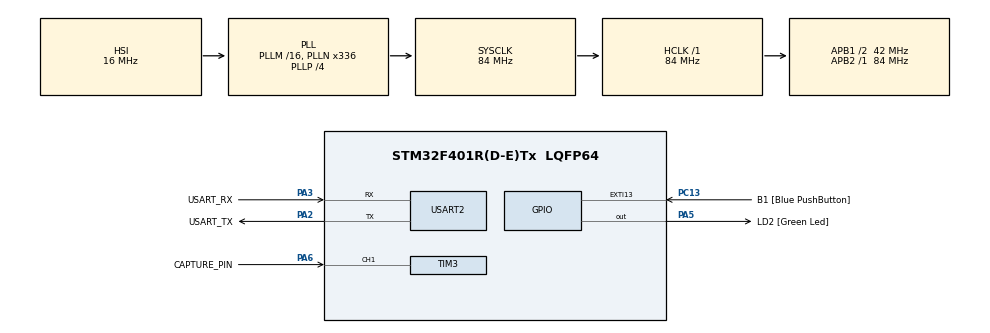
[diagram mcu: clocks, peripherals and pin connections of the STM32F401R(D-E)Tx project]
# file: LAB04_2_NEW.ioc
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Mcu.Family=STM32F4
Mcu.Name=STM32F401R(D-E)Tx
Mcu.Package=LQFP64
NVIC.PriorityGroup=NVIC_PRIORITYGROUP_0
NVIC.TIM2_IRQn=true\:0\:0\:false\:false\:true\:true\:true
NVIC.TIM3_IRQn=true\:0\:0\:false\:false\:true\:true\:true
NVIC.USART2_IRQn=true\:0\:0\:false\:false\:true\:true\:true
PA13.GPIO_Label=TMS
PA13.Mode=Serial_Wire
PA13.Signal=SYS_JTMS-SWDIO
PA14.GPIO_Label=TCK
PA14.Mode=Serial_Wire
PA14.Signal=SYS_JTCK-SWCLK
PA2.GPIO_Label=USART_TX
PA2.GPIO_Mode=GPIO_MODE_AF_PP
PA2.GPIO_PuPd=GPIO_NOPULL
PA2.GPIO_Speed=GPIO_SPEED_FREQ_LOW
PA2.Mode=Asynchronous
PA2.Signal=USART2_TX
PA3.GPIO_Label=USART_RX
PA3.GPIO_Mode=GPIO_MODE_AF_PP
PA3.GPIO_PuPd=GPIO_NOPULL
PA3.GPIO_Speed=GPIO_SPEED_FREQ_LOW
PA3.Mode=Asynchronous
PA3.Signal=USART2_RX
PA5.GPIO_Label=LD2 [Green Led]
PA5.GPIO_Mode=GPIO_MODE_OUTPUT_PP
PA5.GPIO_PuPd=GPIO_NOPULL
PA5.GPIO_Speed=GPIO_SPEED_FREQ_LOW
PA5.Signal=GPIO_Output
PA6.GPIO_Label=CAPTURE_PIN
PA6.Signal=S_TIM3_CH1
PB3.GPIO_Label=SWO
PB3.Signal=SYS_JTDO-SWO
PC13-ANTI_TAMP.GPIO_Label=B1 [Blue PushButton]
PC13-ANTI_TAMP.GPIO_ModeDefaultEXTI=GPIO_MODE_IT_FALLING
PC13-ANTI_TAMP.GPIO_PuPd=GPIO_NOPULL
PC13-ANTI_TAMP.Signal=GPXTI13
PC14-OSC32_IN.Mode=LSE-External-Oscillator
PC14-OSC32_IN.Signal=RCC_OSC32_IN
PC15-OSC32_OUT.Mode=LSE-External-Oscillator
PC15-OSC32_OUT.Signal=RCC_OSC32_OUT
PH0\ -\ OSC_IN.Mode=HSE-External-Clock-Source
PH0\ -\ OSC_IN.Signal=RCC_OSC_IN
PH1\ -\ OSC_OUT.Mode=HSE-External-Clock-Source
PH1\ -\ OSC_OUT.Signal=RCC_OSC_OUT
ProjectManager.HeapSize=0x200
ProjectManager.StackSize=0x400
ProjectManager.TargetToolchain=STM32CubeIDE
RCC.48MHZClocksFreq_Value=48000000
RCC.AHBFreq_Value=84000000
RCC.APB1CLKDivider=RCC_HCLK_DIV2
RCC.APB1Freq_Value=42000000
RCC.APB1TimFreq_Value=84000000
RCC.APB2Freq_Value=84000000
RCC.APB2TimFreq_Value=84000000
RCC.CortexFreq_Value=84000000
RCC.HCLKFreq_Value=84000000
RCC.HSE_VALUE=8000000
RCC.HSI_VALUE=16000000
RCC.PLLN=336
RCC.PLLP=RCC_PLLP_DIV4
RCC.PLLQ=7
RCC.SYSCLKFreq_VALUE=84000000
RCC.SYSCLKSource=RCC_SYSCLKSOURCE_PLLCLK
RCC.VCOOutputFreq_Value=336000000
SH.S_TIM3_CH1.0=TIM3_CH1,Input_Capture1_from_TI1
TIM2.Channel-Output\ Compare1\ No\ Output=TIM_CHANNEL_1
TIM2.Period=999
TIM2.Prescaler=839
TIM3.Channel-Input_Capture1_from_TI1=TIM_CHANNEL_1
USART2.VirtualMode=VM_ASYNC
VP_TIM2_VS_ClockSourceINT.Mode=Internal
VP_TIM2_VS_no_output1.Mode=Output Compare1 No Output
VP_TIM3_VS_ClockSourceINT.Mode=Internal
board=NUCLEO-F401RE

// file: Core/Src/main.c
/* USER CODE BEGIN Header */
/**
  ******************************************************************************
  * @file           : main.c
  * @brief          : Main program body
  ******************************************************************************
  * @attention
  *
  * <h2><center>&copy; Copyright (c) 2023 STMicroelectronics.
  * All rights reserved.</center></h2>
  *
  * This software component is licensed by ST under BSD 3-Clause license,
  * the "License"; You may not use this file except in compliance with the
  * License. You may obtain a copy of the License at:
  *                        opensource.org/licenses/BSD-3-Clause
  *
  ******************************************************************************
  */
/* USER CODE END Header */
#include "main.h"

/* USER CODE BEGIN Includes */
#include "string.h"
#include <stdio.h>
#include <stdlib.h>
/* USER CODE END Includes */

/* USER CODE BEGIN PD */
#define CAPTURING 0
#define DONE 1
#define NONE 0
#define RISING 1
#define FALLING 2
#define MAX_COMPARE_VALUE 91
/* USER CODE END PD */

TIM_HandleTypeDef htim2;
TIM_HandleTypeDef htim3;

UART_HandleTypeDef huart2;

/* USER CODE BEGIN PV */
char msg[30];
char receivedData[3];
char test[] = "\rHo catturato qualcosa!\r\n";
char msg_overflow[] = "\rOverflow!\r\n";
volatile uint8_t number_of_overflows = 0;
volatile uint8_t number_of_overflows_fall = 0;
volatile uint8_t captured_edge = 0;
volatile uint16_t cnt_1 = 0;
volatile uint16_t cnt_2 = 0;
volatile uint16_t cnt_fall = 0;
volatile uint16_t delta_cnt = 0;
volatile uint8_t processing = 0;
volatile uint16_t delta_fall = 0;
volatile uint16_t frequency;
volatile uint8_t max_frequency = 0;
volatile uint8_t min_frequency = 0;
volatile uint8_t dutycycle;
volatile uint8_t read_buffer_new = 0;
volatile uint8_t counting_fall_overflows = 0;
volatile uint8_t counting_overflows = 0;
volatile uint8_t variables_reset = 0;
volatile uint8_t have_received_data = 0;
volatile int8_t opt = 0;
volatile uint8_t step_1 = RESET;
volatile uint8_t step_2 = RESET;
volatile uint8_t step_3 = RESET;
volatile uint8_t compare_value_low = 1;
volatile uint8_t compare_value_high = 11;
uint32_t new_prescaler_value = 4199;
char readBuf[1];
char msg[30];
volatile uint8_t user_choice = 0;
/* USER CODE END PV */

void SystemClock_Config(void);
static void MX_GPIO_Init(void);
static void MX_USART2_UART_Init(void);
static void MX_TIM2_Init(void);
static void MX_TIM3_Init(void);
/* USER CODE BEGIN PFP */
void processReceivedValue(int8_t opt);
int8_t readReceivedValue(void);
void processCapturedEdge(uint8_t edge_type);//
/* USER CODE END PFP */

int main(void)
{

  /* MCU Configuration--------------------------------------------------------*/

  /* Reset of all peripherals, Initializes the Flash interface and the Systick. */
  HAL_Init();

  /* Configure the system clock */
  SystemClock_Config();

  /* Initialize all configured peripherals */
  MX_GPIO_Init();
  MX_USART2_UART_Init();
  MX_TIM2_Init();
  MX_TIM3_Init();
  /* USER CODE BEGIN 2 */
  HAL_TIM_OC_Start_IT(&htim2,TIM_CHANNEL_1);
  HAL_TIM_IC_Start_IT(&htim3,TIM_CHANNEL_1);
  /* USER CODE END 2 */

  /* Infinite loop */
  /* USER CODE BEGIN WHILE */
  HAL_UART_Receive_IT(&huart2, (uint8_t*)readBuf, 1); //initialize reception
  step_1 = SET; //initialize captured edge processing
  while (1)
  {
	  opt = readReceivedValue();
	  if (opt > 0){
		  processReceivedValue(opt);
	  }
    /* USER CODE END WHILE */

  }
}

void SystemClock_Config(void)
{
  RCC_OscInitTypeDef RCC_OscInitStruct = {0};
  RCC_ClkInitTypeDef RCC_ClkInitStruct = {0};

  /** Configure the main internal regulator output voltage
  */
  __HAL_RCC_PWR_CLK_ENABLE();
  __HAL_PWR_VOLTAGESCALING_CONFIG(PWR_REGULATOR_VOLTAGE_SCALE2);
  /** Initializes the RCC Oscillators according to the specified parameters
  * in the RCC_OscInitTypeDef structure.
  */
  RCC_OscInitStruct.OscillatorType = RCC_OSCILLATORTYPE_HSI;
  RCC_OscInitStruct.HSIState = RCC_HSI_ON;
  RCC_OscInitStruct.HSICalibrationValue = RCC_HSICALIBRATION_DEFAULT;
  RCC_OscInitStruct.PLL.PLLState = RCC_PLL_ON;
  RCC_OscInitStruct.PLL.PLLSource = RCC_PLLSOURCE_HSI;
  RCC_OscInitStruct.PLL.PLLM = 16;
  RCC_OscInitStruct.PLL.PLLN = 336;
  RCC_OscInitStruct.PLL.PLLP = RCC_PLLP_DIV4;
  RCC_OscInitStruct.PLL.PLLQ = 7;
  if (HAL_RCC_OscConfig(&RCC_OscInitStruct) != HAL_OK)
  {
    Error_Handler();
  }
  /** Initializes the CPU, AHB and APB buses clocks
  */
  RCC_ClkInitStruct.ClockType = RCC_CLOCKTYPE_HCLK|RCC_CLOCKTYPE_SYSCLK
                              |RCC_CLOCKTYPE_PCLK1|RCC_CLOCKTYPE_PCLK2;
  RCC_ClkInitStruct.SYSCLKSource = RCC_SYSCLKSOURCE_PLLCLK;
  RCC_ClkInitStruct.AHBCLKDivider = RCC_SYSCLK_DIV1;
  RCC_ClkInitStruct.APB1CLKDivider = RCC_HCLK_DIV2;
  RCC_ClkInitStruct.APB2CLKDivider = RCC_HCLK_DIV1;

  if (HAL_RCC_ClockConfig(&RCC_ClkInitStruct, FLASH_LATENCY_2) != HAL_OK)
  {
    Error_Handler();
  }
}

static void MX_TIM2_Init(void)
{

  TIM_ClockConfigTypeDef sClockSourceConfig = {0};
  TIM_MasterConfigTypeDef sMasterConfig = {0};
  TIM_OC_InitTypeDef sConfigOC = {0};

  htim2.Instance = TIM2;
  htim2.Init.Prescaler = 8399;
  htim2.Init.CounterMode = TIM_COUNTERMODE_UP;
  htim2.Init.Period = 99;
  htim2.Init.ClockDivision = TIM_CLOCKDIVISION_DIV1;
  htim2.Init.AutoReloadPreload = TIM_AUTORELOAD_PRELOAD_DISABLE;
  if (HAL_TIM_Base_Init(&htim2) != HAL_OK)
  {
    Error_Handler();
  }
  sClockSourceConfig.ClockSource = TIM_CLOCKSOURCE_INTERNAL;
  if (HAL_TIM_ConfigClockSource(&htim2, &sClockSourceConfig) != HAL_OK)
  {
    Error_Handler();
  }
  if (HAL_TIM_OC_Init(&htim2) != HAL_OK)
  {
    Error_Handler();
  }
  sMasterConfig.MasterOutputTrigger = TIM_TRGO_RESET;
  sMasterConfig.MasterSlaveMode = TIM_MASTERSLAVEMODE_DISABLE;
  if (HAL_TIMEx_MasterConfigSynchronization(&htim2, &sMasterConfig) != HAL_OK)
  {
    Error_Handler();
  }
  sConfigOC.OCMode = TIM_OCMODE_TIMING;
  sConfigOC.Pulse = 0;
  sConfigOC.OCPolarity = TIM_OCPOLARITY_HIGH;
  sConfigOC.OCFastMode = TIM_OCFAST_DISABLE;
  if (HAL_TIM_OC_ConfigChannel(&htim2, &sConfigOC, TIM_CHANNEL_1) != HAL_OK)
  {
    Error_Handler();
  }
  /* USER CODE BEGIN TIM2_Init 2 */
//  htim2.Init.Prescaler = new_prescaler_value;
  /* USER CODE END TIM2_Init 2 */

}

static void MX_TIM3_Init(void)
{

  /* USER CODE BEGIN TIM3_Init 0 */
//	__HAL_TIM_ENABLE_IT(&htim3, TIM_IT_UPDATE);
  /* USER CODE END TIM3_Init 0 */

  TIM_ClockConfigTypeDef sClockSourceConfig = {0};
  TIM_MasterConfigTypeDef sMasterConfig = {0};
  TIM_IC_InitTypeDef sConfigIC = {0};

  /* USER CODE BEGIN TIM3_Init 1 */
//  __HAL_TIM_ENABLE_IT(&htim3, TIM_IT_UPDATE);
  /* USER CODE END TIM3_Init 1 */
  htim3.Instance = TIM3;
  htim3.Init.Prescaler = 167;
  htim3.Init.CounterMode = TIM_COUNTERMODE_UP;
  htim3.Init.Period = 9999;
  htim3.Init.ClockDivision = TIM_CLOCKDIVISION_DIV1;
  htim3.Init.AutoReloadPreload = TIM_AUTORELOAD_PRELOAD_DISABLE;
  if (HAL_TIM_Base_Init(&htim3) != HAL_OK)
  {
    Error_Handler();
  }
  sClockSourceConfig.ClockSource = TIM_CLOCKSOURCE_INTERNAL;
  if (HAL_TIM_ConfigClockSource(&htim3, &sClockSourceConfig) != HAL_OK)
  {
    Error_Handler();
  }
  if (HAL_TIM_IC_Init(&htim3) != HAL_OK)
  {
    Error_Handler();
  }
  sMasterConfig.MasterOutputTrigger = TIM_TRGO_RESET;
  sMasterConfig.MasterSlaveMode = TIM_MASTERSLAVEMODE_DISABLE;
  if (HAL_TIMEx_MasterConfigSynchronization(&htim3, &sMasterConfig) != HAL_OK)
  {
    Error_Handler();
  }
  sConfigIC.ICPolarity = TIM_INPUTCHANNELPOLARITY_BOTHEDGE;
  sConfigIC.ICSelection = TIM_ICSELECTION_DIRECTTI;
  sConfigIC.ICPrescaler = TIM_ICPSC_DIV1;
  sConfigIC.ICFilter = 0;
  if (HAL_TIM_IC_ConfigChannel(&htim3, &sConfigIC, TIM_CHANNEL_1) != HAL_OK)
  {
    Error_Handler();
  }
  /* USER CODE BEGIN TIM3_Init 2 */
  //Enables the TIM_IT_UPDATE interrupt -> enables PeriodElapsed callback
  __HAL_TIM_ENABLE_IT(&htim3, TIM_IT_UPDATE);
  /* USER CODE END TIM3_Init 2 */

}

static void MX_USART2_UART_Init(void)
{

  huart2.Instance = USART2;
  huart2.Init.BaudRate = 115200;
  huart2.Init.WordLength = UART_WORDLENGTH_8B;
  huart2.Init.StopBits = UART_STOPBITS_1;
  huart2.Init.Parity = UART_PARITY_NONE;
  huart2.Init.Mode = UART_MODE_TX_RX;
  huart2.Init.HwFlowCtl = UART_HWCONTROL_NONE;
  huart2.Init.OverSampling = UART_OVERSAMPLING_16;
  if (HAL_UART_Init(&huart2) != HAL_OK)
  {
    Error_Handler();
  }

}

static void MX_GPIO_Init(void)
{
  GPIO_InitTypeDef GPIO_InitStruct = {0};

  /* GPIO Ports Clock Enable */
  __HAL_RCC_GPIOC_CLK_ENABLE();
  __HAL_RCC_GPIOH_CLK_ENABLE();
  __HAL_RCC_GPIOA_CLK_ENABLE();
  __HAL_RCC_GPIOB_CLK_ENABLE();

  /*Configure GPIO pin Output Level */
  HAL_GPIO_WritePin(LD2_GPIO_Port, LD2_Pin, GPIO_PIN_RESET);

  /*Configure GPIO pin Output Level */
  HAL_GPIO_WritePin(SQUARE_WAVE_GPIO_Port, SQUARE_WAVE_Pin, GPIO_PIN_RESET);

  /*Configure GPIO pin : B1_Pin */
  GPIO_InitStruct.Pin = B1_Pin;
  GPIO_InitStruct.Mode = GPIO_MODE_IT_FALLING;
  GPIO_InitStruct.Pull = GPIO_NOPULL;
  HAL_GPIO_Init(B1_GPIO_Port, &GPIO_InitStruct);

  /*Configure GPIO pin : LD2_Pin */
  GPIO_InitStruct.Pin = LD2_Pin;
  GPIO_InitStruct.Mode = GPIO_MODE_OUTPUT_PP;
  GPIO_InitStruct.Pull = GPIO_NOPULL;
  GPIO_InitStruct.Speed = GPIO_SPEED_FREQ_LOW;
  HAL_GPIO_Init(LD2_GPIO_Port, &GPIO_InitStruct);

  /*Configure GPIO pin : SQUARE_WAVE_Pin */
  GPIO_InitStruct.Pin = SQUARE_WAVE_Pin;
  GPIO_InitStruct.Mode = GPIO_MODE_OUTPUT_PP;
  GPIO_InitStruct.Pull = GPIO_NOPULL;
  GPIO_InitStruct.Speed = GPIO_SPEED_FREQ_LOW;
  HAL_GPIO_Init(SQUARE_WAVE_GPIO_Port, &GPIO_InitStruct);

}

/* USER CODE BEGIN 4 */
//callback function associated to output compare's capture event
void HAL_TIM_OC_DelayElapsedCallback(TIM_HandleTypeDef * htim) {
	if (htim->Instance == TIM2){
		// toggle the pin where the square wave is to be generated
		HAL_GPIO_TogglePin(GPIOC, GPIO_PIN_9);
		// we want two capture events per period of the timer
		if (TIM2->CCR1 == compare_value_high) {
			TIM2->CCR1 = compare_value_low;
		}
		else TIM2->CCR1 = compare_value_high;
	}
}
//callback function associated to input capture
void HAL_TIM_IC_CaptureCallback(TIM_HandleTypeDef * htim){
	// if the pin is high after the compare event,
	// it means the latest capture edge was rising
	if (HAL_GPIO_ReadPin(GPIOA, GPIO_PIN_6) == GPIO_PIN_SET){
		captured_edge = RISING;
	}
	// if it is low, then it's a falling edge
	else if (HAL_GPIO_ReadPin(GPIOA, GPIO_PIN_6) == GPIO_PIN_RESET){
		captured_edge = FALLING;
	}
	// function that computes frequency and duty cycle
	processCapturedEdge(captured_edge);
}

// this function is used to count the number of overflows that occur
// between edges
void HAL_TIM_PeriodElapsedCallback(TIM_HandleTypeDef * htim){
	if (htim->Instance == TIM3){
		// if counting_overflows is 1, increase the count of overflows
		// between cnt_1 and cnt_2 every time this function is called
		// also increase the number of overflows between cnt_1 and cnt_fall
		// is counting_fall_overflows is 1
		if (counting_overflows != 0) {
			number_of_overflows++;
			if (counting_fall_overflows != 0) number_of_overflows_fall++;
		}
	}
}

int8_t readReceivedValue(void){
	int8_t retVal = -1;
	if (have_received_data == SET){
		have_received_data = RESET;
		  HAL_UART_Receive_IT(&huart2, (uint8_t*)readBuf, 1);
		  retVal = atoi(readBuf);
	}
	return retVal;
}
void processReceivedValue(int8_t opt){
	// based on the value passed by the user via UART,
	// transmit either frequency or duty cycle
	switch (opt) {
	case 1:
		sprintf(msg, "Current frequency: %u\r\n", frequency);
		HAL_UART_Transmit_IT(&huart2, (uint8_t*)msg, strlen(msg));
		break;
	case 2:
		sprintf(msg, "Current duty cycle: %u\r\n", dutycycle);
		HAL_UART_Transmit_IT(&huart2, (uint8_t*)msg, strlen(msg));
		break;
	}
}
// to determine frequency and duty cycle, we need 3 captures:
// first rising edge, second rising edge, falling edge in between
// we have implemented this as a 3-step process:
void processCapturedEdge(uint8_t captured_edge){
	// in the first step the captured value is assigned to cnt_1
	// and we start counting overflows
	if (captured_edge == RISING && step_1 == SET){
		step_1 = RESET;
		///////////////
		cnt_1 = TIM3->CCR1; // count at first rising edge
		number_of_overflows = 0; // reset the number of overflows
		number_of_overflows_fall = 0;
		counting_fall_overflows = 1; // count overflows of TIM3 btw cnt_1 and cnt_fall
		counting_overflows= 1; // start counting overflows of TIM3 between cnt_1 and cnt_2
		///////////////
		step_2 = SET;
	}
	// in the second step the captured value is assigned to cnt_fall
	else if (captured_edge == FALLING && step_2 == SET){
		step_2 = RESET;
		///////////////
		cnt_fall = TIM3->CCR1; // count at falling edge
		counting_fall_overflows = 0; // stop counting overflows
		// delta_fall = # of timer ticks between cnt_fall and cnt_2
		delta_fall = cnt_fall + number_of_overflows_fall*10000 - cnt_1;
		///////////////
		step_3 = SET;
	}
	// in the third step the captured value is assigned to cnt_2,
	// then frequency and duty cycle are calculated
	else if (captured_edge == RISING && step_3 == SET){
		step_3 = RESET;
		///////////////
		cnt_2 = TIM3->CCR1; // count at second rising edge
		counting_overflows = 0; // stop counting overflows
		// delta_cnt = # of timer ticks b/w cnt_1 and cnt_2
		delta_cnt = cnt_2 + number_of_overflows*10000 - cnt_1;
		frequency = 50*10000/delta_cnt; // 50 is UEF of TIM3, 10000 is the period
		dutycycle = 100*delta_fall/delta_cnt;
		///////////////
		step_1 = SET;
	}
}

void HAL_UART_RxCpltCallback(UART_HandleTypeDef *huart){
	// this variable is used in the ReadReceivedValue function
	// to prevent reading the content of the receive buffer
	// over and over again
	have_received_data = SET;
}
/* USER CODE END 4 */

void Error_Handler(void)
{
  __disable_irq();
  while (1)
  {
  }
}

/************************ (C) COPYRIGHT STMicroelectronics *****END OF FILE****/
